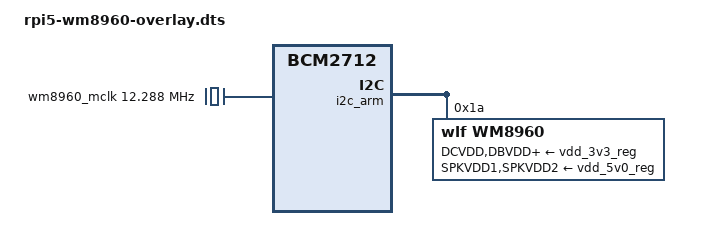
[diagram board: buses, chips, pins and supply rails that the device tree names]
/*
 * WM8960音频设备树配置 - 超简单版本
 *
 * 这个文件告诉Linux内核硬件是如何连接的：
 *
 * 树莓派5 → I2S控制器 → (音频数据线) → WM8960编解码器 → 扬声器/耳机
 *              ↑                                   ↑
 *           时钟信号                           时钟信号
 *
 * 设计原则：
 * - 每个配置都有清晰的注释
 * - 配置分组明确
 * - 保持最小必要配置
 */

/dts-v1/;  // 设备树格式版本
/plugin/;  // 这是设备树插件（overlay）

/ {
	// =========================================================================
	// 根节点配置
	// =========================================================================

	compatible = "brcm,bcm2712";  // 兼容树莓派5 (BCM2712芯片)

	// =========================================================================
	// 片段1：启用I2S控制器
	// 作用：激活树莓派5的I2S音频接口
	// =========================================================================

	fragment@0 {
		target = <&i2s_clk_producer>;  // 目标：I2S时钟生产者设备
		__overlay__ {
			status = "okay";           // 状态：启用这个设备
		};
	};

	// =========================================================================
	// 片段2：创建主时钟
	// 作用：为WM8960编解码器提供12.288MHz的主时钟
	// =========================================================================

	fragment@1 {
		target-path = "/";             // 目标：设备树的根节点
		__overlay__ {
			wm8960_mclk: wm8960_mclk {  // 节点标签：供其他地方引用
				compatible = "fixed-clock";    // 类型：固定频率时钟
				#clock-cells = <0>;            // 时钟参数数量（不需要参数）
				clock-frequency = <12288000>; // 频率：12.288 MHz
			};
		};
	};

	// =========================================================================
	// 片段3：配置WM8960编解码器
	// 作用：定义WM8960芯片的硬件连接和电源供应
	// =========================================================================

	fragment@2 {
		target = <&i2c_arm>;          // 目标：I2C控制器
		__overlay__ {
			#address-cells = <1>;     // I2C地址格式
			#size-cells = <0>;        // I2C数据格式
			status = "okay";          // 启用I2C控制器

			// WM8960编解码器节点
			wm8960: wm8960@1a {       // 节点标签：地址0x1a
				compatible = "wlf,wm8960";     // 芯片型号
				reg = <0x1a>;                   // I2C地址：0x1a
				#sound-dai-cells = <0>;         // DAI接口参数数量

				// 时钟配置
				clocks = <&wm8960_mclk>;       // 使用上面的时钟
				clock-names = "mclk";          // 时钟名称

				// 电源供应配置（连接到树莓派的电源调节器）
				DCVDD-supply = <&vdd_3v3_reg>;  // 数字核心电源
				DBVDD-supply = <&vdd_3v3_reg>;  // 数字缓冲电源
				AVDD-supply  = <&vdd_3v3_reg>;  // 模拟电源
				SPKVDD1-supply = <&vdd_5v0_reg>; // 扬声器1电源
				SPKVDD2-supply = <&vdd_5v0_reg>; // 扬声器2电源
			};
		};
	};

	// =========================================================================
	// 片段4：定义声卡
	// 作用：告诉ASoC框架如何连接I2S控制器和WM8960编解码器
	// =========================================================================

	fragment@3 {
		target-path = "/";             // 目标：根节点
		__overlay__ {
			sound {                      // 声卡节点
				compatible = "raspberrypi,rpi-wm8960-soundcard"; // 驱动匹配标识

				// 硬件连接定义
				i2s-controller = <&i2s_clk_producer>; // CPU端：I2S控制器
				audio-codec = <&wm8960>;              // Codec端：WM8960芯片

				status = "okay";          // 启用这个声卡
			};
		};
	};
};
